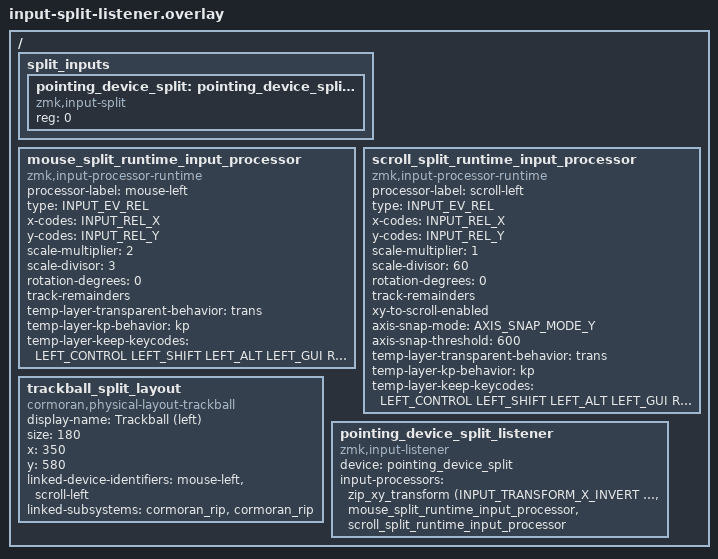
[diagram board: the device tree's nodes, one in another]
#include <dt-bindings/zmk/keys.h>
#include <dt-bindings/zmk/input_transform.h>
#include <dt-bindings/zmk/runtime_input_processor.h>
#include <zephyr/dt-bindings/input/input-event-codes.h>

/{
    split_inputs {
        #address-cells = <1>;
        #size-cells = <0>;

        pointing_device_split: pointing_device_split@0 {
            compatible = "zmk,input-split";
            reg = <0>;
        };
    };

    /*
     * 左のトラックボール用。右と同じ processor インスタンスを使い回すと
     * 感度や端数の状態を共有してしまうため、専用のものを定義する。
     * DYA Studio の Trackball タブにはラベル名で並ぶ。
     */
    mouse_split_runtime_input_processor: mouse_split_runtime_input_processor {
        compatible = "zmk,input-processor-runtime";
        processor-label = "mouse-left";
        type = <INPUT_EV_REL>;
        x-codes = <INPUT_REL_X>;
        y-codes = <INPUT_REL_Y>;
        scale-multiplier = <2>;
        scale-divisor = <3>;
        rotation-degrees = <0>;
        track-remainders;

        temp-layer-transparent-behavior = <&trans>;
        temp-layer-kp-behavior = <&kp>;
        temp-layer-keep-keycodes = <LEFT_CONTROL LEFT_SHIFT LEFT_ALT LEFT_GUI RIGHT_CONTROL RIGHT_SHIFT RIGHT_ALT RIGHT_GUI>;

        #input-processor-cells = <0>;
    };

    scroll_split_runtime_input_processor: scroll_split_runtime_input_processor {
        compatible = "zmk,input-processor-runtime";
        processor-label = "scroll-left";
        type = <INPUT_EV_REL>;
        x-codes = <INPUT_REL_X>;
        y-codes = <INPUT_REL_Y>;
        scale-multiplier = <1>;
        scale-divisor = <60>;
        rotation-degrees = <0>;
        track-remainders;
        xy-to-scroll-enabled;

        axis-snap-mode = <AXIS_SNAP_MODE_Y>;
        axis-snap-threshold = <600>;

        temp-layer-transparent-behavior = <&trans>;
        temp-layer-kp-behavior = <&kp>;
        temp-layer-keep-keycodes = <LEFT_CONTROL LEFT_SHIFT LEFT_ALT LEFT_GUI RIGHT_CONTROL RIGHT_SHIFT RIGHT_ALT RIGHT_GUI>;

        #input-processor-cells = <0>;
    };

    /* DYA Studio のプレビュー用。座標は表示専用 */
    trackball_split_layout: trackball_split_layout {
        compatible = "cormoran,physical-layout-trackball";
        display-name = "Trackball (left)";
        size = <180>;
        x = <350>;
        y = <580>;

        linked-device-identifiers = "mouse-left", "scroll-left";
        linked-subsystems = "cormoran_rip", "cormoran_rip";
    };

    pointing_device_split_listener: pointing_device_split_listener {
        compatible = "zmk,input-listener";
        device = <&pointing_device_split>;
        status = "okay";
        input-processors = <&zip_xy_transform (INPUT_TRANSFORM_X_INVERT | INPUT_TRANSFORM_Y_INVERT)>,
                           <&mouse_split_runtime_input_processor>,
                           <&scroll_split_runtime_input_processor>;
     };
};
